# ATSAMA5D36 register map
Vendor: Microchip Technology; Series: SAMA5D3; File version: 0
Registers are 32-bit, read-write, reset 0x0 unless marked. A register's access mark holds for its fields unless they carry their own. Offsets are from the block's base; [hi:lo] are bit positions; {n}, {i} and the like mark numbered series; 'fields as' and 'values as' point back to an identical list.

## USART0 — Universal Synchronous Asynchronous Receiver Transmitter
Base 0xF001C000; register names take the prefix USART_
Same registers: USART1 0xF0020000, USART2 0xF8020000, USART3 0xF8024000
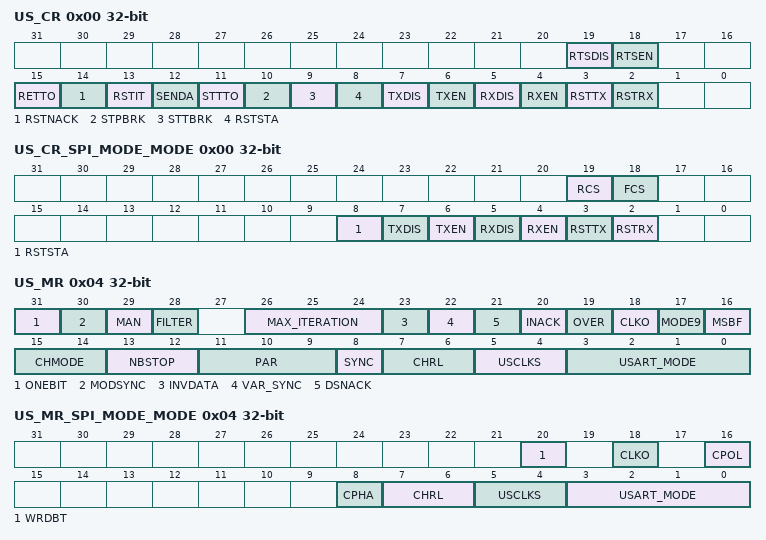
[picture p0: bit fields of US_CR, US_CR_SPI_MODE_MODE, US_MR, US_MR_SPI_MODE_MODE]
0x00 US_CR wo — Control Register
  [19] RTSDIS — Request to Send Pin Control
  [18] RTSEN — Request to Send Pin Control
  [15] RETTO — Start Time-out Immediately
  [14] RSTNACK — Reset Non Acknowledge
  [13] RSTIT — Reset Iterations
  [12] SENDA — Send Address
  [11] STTTO — Clear TIMEOUT Flag and Start Time-out After Next Character Received
  [10] STPBRK — Stop Break
  [9] STTBRK — Start Break
  [8] RSTSTA — Reset Status Bits
  [7] TXDIS — Transmitter Disable
  [6] TXEN — Transmitter Enable
  [5] RXDIS — Receiver Disable
  [4] RXEN — Receiver Enable
  [3] RSTTX — Reset Transmitter
  [2] RSTRX — Reset Receiver
0x00 US_CR_SPI_MODE_MODE wo (alternate view of US_CR) — Control Register
  [19] RCS — Release SPI Chip Select
  [18] FCS — Force SPI Chip Select
  [8] RSTSTA — Reset Status Bits
  [7] TXDIS — Transmitter Disable
  [6] TXEN — Transmitter Enable
  [5] RXDIS — Receiver Disable
  [4] RXEN — Receiver Enable
  [3] RSTTX — Reset Transmitter
  [2] RSTRX — Reset Receiver
0x04 US_MR — Mode Register
  [31] ONEBIT — Start Frame Delimiter Selector
  [30] MODSYNC — Manchester Synchronization Mode
  [29] MAN — Manchester Encoder/Decoder Enable
  [28] FILTER — Receive Line Filter
  [26:24] MAX_ITERATION — Maximum Number of Automatic Iteration
  [23] INVDATA — Inverted Data
  [22] VAR_SYNC — Variable Synchronization of Command/Data Sync Start Frame Delimiter
  [21] DSNACK — Disable Successive NACK
  [20] INACK — Inhibit Non Acknowledge
  [19] OVER — Oversampling Mode
  [18] CLKO — Clock Output Select
  [17] MODE9 — 9-bit Character Length
  [16] MSBF — Bit Order
  [15:14] CHMODE — Channel Mode
    0=NORMAL (Normal mode); 1=AUTOMATIC (Automatic Echo. Receiver input is connected to the TXD pin.); 2=LOCAL_LOOPBACK (Local Loopback. Transmitter output is connected to the Receiver Input.); 3=REMOTE_LOOPBACK (Remote Loopback. RXD pin is internally connected to the TXD pin.)
  [13:12] NBSTOP — Number of Stop Bits
    0=_1_BIT (1 stop bit); 1=_1_5_BIT (1.5 stop bit (SYNC = 0) or reserved (SYNC = 1)); 2=_2_BIT (2 stop bits)
  [11:9] PAR — Parity Type
    0=EVEN (Even parity); 1=ODD (Odd parity); 2=SPACE (Parity forced to 0 (Space)); 3=MARK (Parity forced to 1 (Mark)); 4=NO (No parity); 6=MULTIDROP (Multidrop mode)
  [8] SYNC — Synchronous Mode Select
  [7:6] CHRL — Character Length
    {v}=_{v+5}_BIT (Character length is {v+5} bits) (v=0..3)
  [5:4] USCLKS — Clock Selection
    0=MCK (Peripheral clock is selected); 1=DIV (Peripheral clock divided (DIV=8) is selected); 3=SCK (Serial clock (SCK) is selected)
  [3:0] USART_MODE — USART Mode of Operation
    0=NORMAL (Normal mode); 1=RS485; 2=HW_HANDSHAKING (Hardware Handshaking); 4=IS07816_T_0 (IS07816 Protocol: T = 0); 6=IS07816_T_1 (IS07816 Protocol: T = 1); 8=IRDA; 14=SPI_MASTER (SPI master mode (CLKO must be written to 1 and USCLKS = 0, 1 or 2)); 15=SPI_SLAVE (SPI Slave mode)
0x04 US_MR_SPI_MODE_MODE (alternate view of US_MR) — Mode Register
  [20] WRDBT — Wait Read Data Before Transfer
  [18] CLKO — Clock Output Select
  [16] CPOL — SPI Clock Polarity
  [8] CPHA — SPI Clock Phase
  [7:6] CHRL — Character Length
    3=_8_BIT (Character length is 8 bits)
  [5:4] USCLKS — Clock Selection
    0=MCK (Peripheral clock is selected); 1=DIV (Peripheral clock divided (DIV=8) is selected); 3=SCK (Serial Clock SLK is selected)
  [3:0] USART_MODE — USART Mode of Operation
    14=SPI_MASTER; 15=SPI_SLAVE
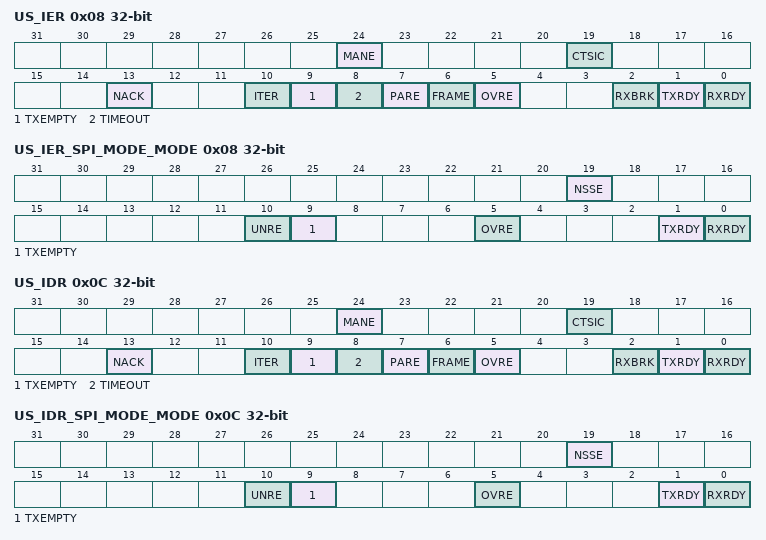
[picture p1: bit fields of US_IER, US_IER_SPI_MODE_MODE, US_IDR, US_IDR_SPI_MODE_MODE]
0x08 US_IER wo — Interrupt Enable Register
  [24] MANE — Manchester Error Interrupt Enable
  [19] CTSIC — Clear to Send Input Change Interrupt Enable
  [13] NACK — Non Acknowledge Interrupt Enable
  [10] ITER — Max number of Repetitions Reached Interrupt Enable
  [9] TXEMPTY — TXEMPTY Interrupt Enable
  [8] TIMEOUT — Time-out Interrupt Enable
  [7] PARE — Parity Error Interrupt Enable
  [6] FRAME — Framing Error Interrupt Enable
  [5] OVRE — Overrun Error Interrupt Enable
  [2] RXBRK — Receiver Break Interrupt Enable
  [1] TXRDY — TXRDY Interrupt Enable
  [0] RXRDY — RXRDY Interrupt Enable
0x08 US_IER_SPI_MODE_MODE wo (alternate view of US_IER) — Interrupt Enable Register
  [19] NSSE — NSS Line (Driving CTS Pin) Rising or Falling Edge Event Interrupt Enable
  [10] UNRE — SPI Underrun Error Interrupt Enable
  [9] TXEMPTY — TXEMPTY Interrupt Enable
  [5] OVRE — Overrun Error Interrupt Enable
  [1] TXRDY — TXRDY Interrupt Enable
  [0] RXRDY — RXRDY Interrupt Enable
0x0C US_IDR wo — Interrupt Disable Register
  [24] MANE — Manchester Error Interrupt Disable
  [19] CTSIC — Clear to Send Input Change Interrupt Disable
  [13] NACK — Non Acknowledge Interrupt Disable
  [10] ITER — Max Number of Repetitions Reached Interrupt Disable
  [9] TXEMPTY — TXEMPTY Interrupt Disable
  [8] TIMEOUT — Time-out Interrupt Disable
  [7] PARE — Parity Error Interrupt Disable
  [6] FRAME — Framing Error Interrupt Disable
  [5] OVRE — Overrun Error Interrupt Enable
  [2] RXBRK — Receiver Break Interrupt Disable
  [1] TXRDY — TXRDY Interrupt Disable
  [0] RXRDY — RXRDY Interrupt Disable
0x0C US_IDR_SPI_MODE_MODE wo (alternate view of US_IDR) — Interrupt Disable Register
  [19] NSSE — NSS Line (Driving CTS Pin) Rising or Falling Edge Event Interrupt Disable
  [10] UNRE — SPI Underrun Error Interrupt Disable
  [9] TXEMPTY — TXEMPTY Interrupt Disable
  [5] OVRE — Overrun Error Interrupt Disable
  [1] TXRDY — TXRDY Interrupt Disable
  [0] RXRDY — RXRDY Interrupt Disable
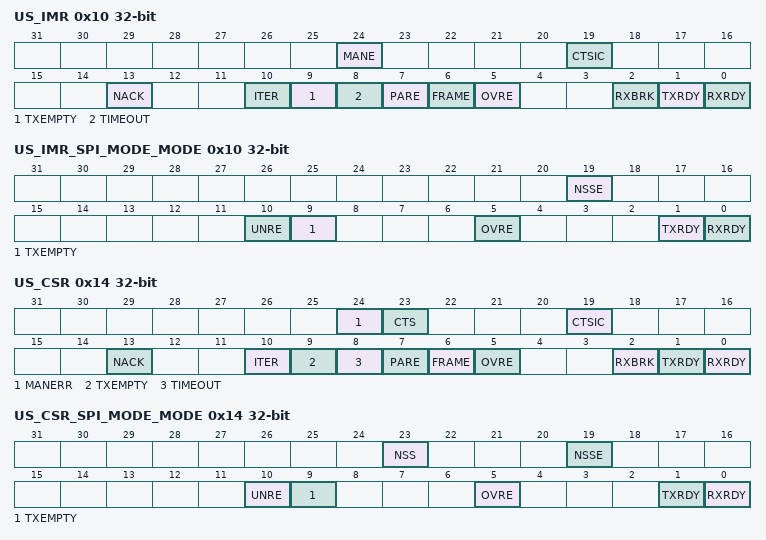
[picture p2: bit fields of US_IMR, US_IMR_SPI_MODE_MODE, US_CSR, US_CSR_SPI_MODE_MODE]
0x10 US_IMR ro — Interrupt Mask Register
  [24] MANE — Manchester Error Interrupt Mask
  [19] CTSIC — Clear to Send Input Change Interrupt Mask
  [13] NACK — Non Acknowledge Interrupt Mask
  [10] ITER — Max Number of Repetitions Reached Interrupt Mask
  [9] TXEMPTY — TXEMPTY Interrupt Mask
  [8] TIMEOUT — Time-out Interrupt Mask
  [7] PARE — Parity Error Interrupt Mask
  [6] FRAME — Framing Error Interrupt Mask
  [5] OVRE — Overrun Error Interrupt Mask
  [2] RXBRK — Receiver Break Interrupt Mask
  [1] TXRDY — TXRDY Interrupt Mask
  [0] RXRDY — RXRDY Interrupt Mask
0x10 US_IMR_SPI_MODE_MODE ro (alternate view of US_IMR) — Interrupt Mask Register
  [19] NSSE — NSS Line (Driving CTS Pin) Rising or Falling Edge Event Interrupt Mask
  [10] UNRE — SPI Underrun Error Interrupt Mask
  [9] TXEMPTY — TXEMPTY Interrupt Mask
  [5] OVRE — Overrun Error Interrupt Mask
  [1] TXRDY — TXRDY Interrupt Mask
  [0] RXRDY — RXRDY Interrupt Mask
0x14 US_CSR ro — Channel Status Register
  [24] MANERR — Manchester Error (cleared by writing a one to the bit US_CR.RSTSTA)
  [23] CTS — Image of CTS Input
  [19] CTSIC — Clear to Send Input Change Flag (cleared on read)
  [13] NACK — Non Acknowledge Interrupt (cleared by writing a one to bit US_CR.RSTNACK)
  [10] ITER — Max Number of Repetitions Reached (cleared by writing a one to bit US_CR.RSTIT)
  [9] TXEMPTY — Transmitter Empty (cleared by writing US_THR)
  [8] TIMEOUT — Receiver Time-out (cleared by writing a one to bit US_CR.STTTO)
  [7] PARE — Parity Error (cleared by writing a one to bit US_CR.RSTSTA)
  [6] FRAME — Framing Error (cleared by writing a one to bit US_CR.RSTSTA)
  [5] OVRE — Overrun Error (cleared by writing a one to bit US_CR.RSTSTA)
  [2] RXBRK — Break Received/End of Break (cleared by writing a one to bit US_CR.RSTSTA)
  [1] TXRDY — Transmitter Ready (cleared by writing US_THR)
  [0] RXRDY — Receiver Ready (cleared by reading US_RHR)
0x14 US_CSR_SPI_MODE_MODE ro (alternate view of US_CSR) — Channel Status Register
  [23] NSS — NSS Line (Driving CTS Pin) Rising or Falling Edge Event (cleared on read)
  [19] NSSE — NSS Line (Driving CTS Pin) Rising or Falling Edge Event (cleared on read)
  [10] UNRE — Underrun Error (cleared by writing a one to bit US_CR.RSTSTA)
  [9] TXEMPTY — Transmitter Empty (cleared by writing US_THR)
  [5] OVRE — Overrun Error (cleared by writing a one to bit US_CR.RSTSTA)
  [1] TXRDY — Transmitter Ready (cleared by writing US_THR)
  [0] RXRDY — Receiver Ready (cleared by reading US_RHR)
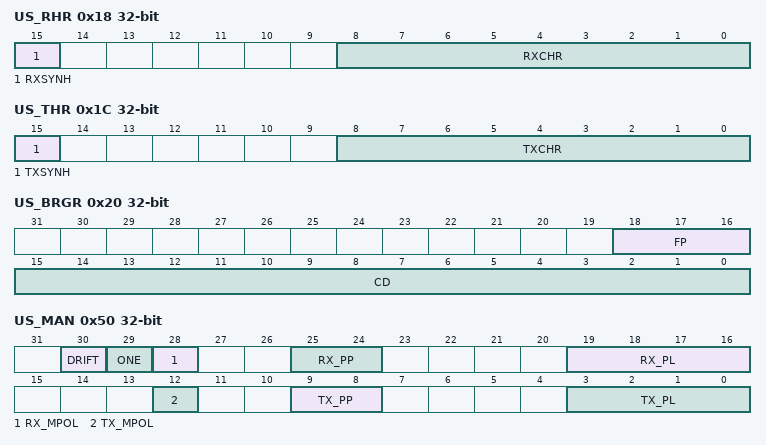
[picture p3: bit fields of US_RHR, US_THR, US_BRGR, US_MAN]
0x18 US_RHR ro — Receive Holding Register
  [15] RXSYNH — Received Sync
  [8:0] RXCHR — Received Character
0x1C US_THR wo — Transmit Holding Register
  [15] TXSYNH — Sync Field to be Transmitted
  [8:0] TXCHR — Character to be Transmitted
0x20 US_BRGR — Baud Rate Generator Register
  [18:16] FP — Fractional Part
  [15:0] CD — Clock Divider
0x24 US_RTOR — Receiver Time-out Register
  [15:0] TO — Time-out Value
0x28 US_TTGR — Transmitter Timeguard Register
  [7:0] TG — Timeguard Value
0x40 US_FIDI — FI DI Ratio Register
  [10:0] FI_DI_RATIO — FI Over DI Ratio Value
0x44 US_NER ro — Number of Errors Register
  [7:0] NB_ERRORS — Number of Errors
0x4C US_IF — IrDA Filter Register
  [7:0] IRDA_FILTER
0x50 US_MAN — Manchester Configuration Register
  [30] DRIFT — Drift Compensation
  [29] ONE — Must Be Set to 1
  [28] RX_MPOL — Receiver Manchester Polarity
  [25:24] RX_PP — Receiver Preamble Pattern detected
    0=ALL_ONE (The preamble is composed of '1's); 1=ALL_ZERO (The preamble is composed of '0's); 2=ZERO_ONE (The preamble is composed of '01's); 3=ONE_ZERO (The preamble is composed of '10's)
  [19:16] RX_PL — Receiver Preamble Length
  [12] TX_MPOL — Transmitter Manchester Polarity
  [9:8] TX_PP — Transmitter Preamble Pattern
    values as RX_PP
  [3:0] TX_PL — Transmitter Preamble Length
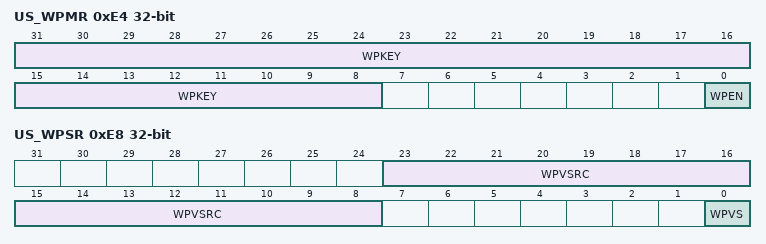
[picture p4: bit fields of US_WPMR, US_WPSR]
0xE4 US_WPMR — Write Protection Mode Register
  [31:8] WPKEY — Write Protection Key
    0x555341=PASSWD (Writing any other value in this field aborts the write operation of the WPEN bit. Always reads as 0.)
  [0] WPEN — Write Protection Enable
0xE8 US_WPSR ro — Write Protection Status Register
  [23:8] WPVSRC — Write Protection Violation Source
  [0] WPVS — Write Protection Violation Status
